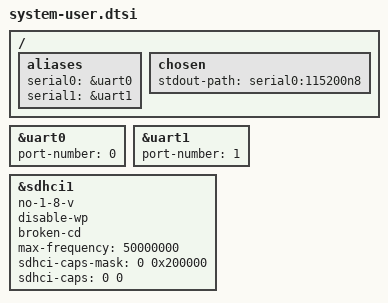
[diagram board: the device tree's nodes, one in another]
/include/ "system-conf.dtsi"
/ {
};

/* 2025.2 gen-machineconf assigns port-number=0 to uart1, making ttyPS0 map
 * to uart1. Vitis bsp.yaml confirms this board uses psu_uart_0, so force
 * ttyPS0 back to uart0. */
&uart0 {
   port-number = <0>;
};
&uart1 {
   port-number = <1>;
};
/ {
   aliases {
      serial0 = &uart0;
      serial1 = &uart1;
   };
   chosen {
      stdout-path = "serial0:115200n8";
   };
};

/* The Vivado design for this repo exports a minimal sdhci1 node (just
 * clock-frequency, status, mio-bank). Without these extra properties
 * Linux times out initialising the SD card with "error -110". Values
 * mirror what the stock 2025.2 xilinx-zcu104 BSP uses. */
&sdhci1 {
   no-1-8-v;
   disable-wp;
   broken-cd;
   max-frequency = <50000000>;
   /* Cap SDR50/HS modes — these bits in SDHCI_CAPABILITIES block faster UHS
    * modes that the ZCU104 level shifter can't sustain. */
   sdhci-caps-mask = <0 0x200000>;
   sdhci-caps = <0 0>;
};
